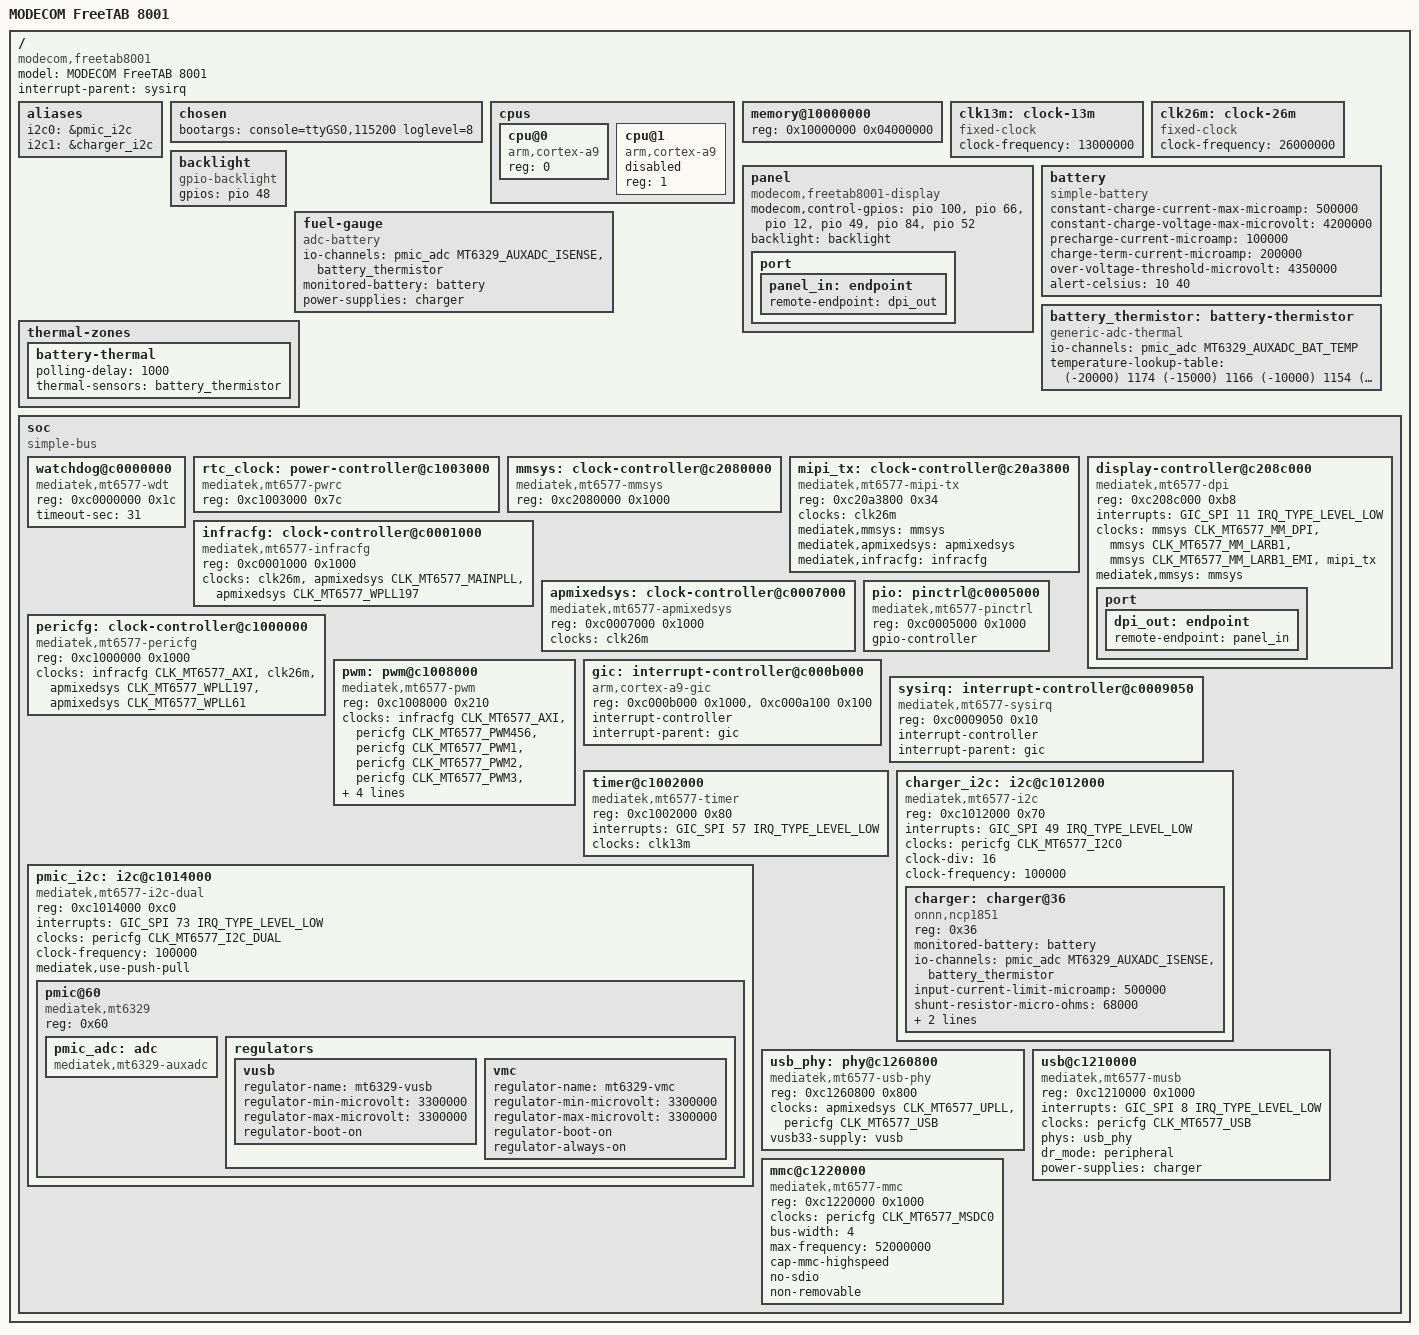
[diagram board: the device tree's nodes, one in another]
// SPDX-License-Identifier: GPL-2.0-only
/dts-v1/;

#include <dt-bindings/interrupt-controller/arm-gic.h>
#include <dt-bindings/interrupt-controller/irq.h>
#include <dt-bindings/clock/mediatek,mt6577-clk.h>
#include <dt-bindings/clock/mediatek,mt6577-mmsys.h>
#include <dt-bindings/gpio/gpio.h>
#include <dt-bindings/iio/adc/mediatek,mt6329-auxadc.h>

/ {
	model = "MODECOM FreeTAB 8001";
	compatible = "modecom,freetab8001", "mediatek,mt6577";
	#address-cells = <1>;
	#size-cells = <1>;
	interrupt-parent = <&sysirq>;

	aliases {
		i2c0 = &pmic_i2c;
		i2c1 = &charger_i2c;
	};

	chosen {
		bootargs = "console=ttyGS0,115200 loglevel=8";
	};

	cpus {
		#address-cells = <1>;
		#size-cells = <0>;

		cpu@0 {
			device_type = "cpu";
			compatible = "arm,cortex-a9";
			reg = <0>;
		};

		cpu@1 {
			device_type = "cpu";
			compatible = "arm,cortex-a9";
			reg = <1>;
			status = "disabled";
		};
	};

	memory@10000000 {
		device_type = "memory";
		reg = <0x10000000 0x04000000>;
	};

	clk13m: clock-13m {
		compatible = "fixed-clock";
		#clock-cells = <0>;
		clock-frequency = <13000000>;
	};

	clk26m: clock-26m {
		compatible = "fixed-clock";
		#clock-cells = <0>;
		clock-frequency = <26000000>;
	};

	backlight: backlight {
		compatible = "gpio-backlight";
		gpios = <&pio 48 GPIO_ACTIVE_HIGH>;
	};

	panel {
		compatible = "modecom,freetab8001-display";
		modecom,control-gpios = <&pio 100 GPIO_ACTIVE_HIGH>,
					<&pio 66 GPIO_ACTIVE_HIGH>,
					<&pio 12 GPIO_ACTIVE_HIGH>,
					<&pio 49 GPIO_ACTIVE_HIGH>,
					<&pio 84 GPIO_ACTIVE_HIGH>,
					<&pio 52 GPIO_ACTIVE_HIGH>;
		backlight = <&backlight>;

		port {
			panel_in: endpoint {
				remote-endpoint = <&dpi_out>;
			};
		};
	};

	battery: battery {
		compatible = "simple-battery";
		constant-charge-current-max-microamp = <500000>;
		constant-charge-voltage-max-microvolt = <4200000>;
		precharge-current-microamp = <100000>;
		charge-term-current-microamp = <200000>;
		over-voltage-threshold-microvolt = <4350000>;
		alert-celsius = <10 40>;
	};

	fuel-gauge {
		compatible = "adc-battery";
		io-channels = <&pmic_adc MT6329_AUXADC_ISENSE>,
			      <&battery_thermistor>;
		io-channel-names = "voltage", "temperature";
		monitored-battery = <&battery>;
		power-supplies = <&charger>;
	};

	battery_thermistor: battery-thermistor {
		compatible = "generic-adc-thermal";
		#thermal-sensor-cells = <0>;
		#io-channel-cells = <0>;
		io-channels = <&pmic_adc MT6329_AUXADC_BAT_TEMP>;
		io-channel-names = "sensor-channel";
		temperature-lookup-table = <
			(-20000) 1174
			(-15000) 1166
			(-10000) 1154
			(-5000) 1140
			0 1122
			5000 1101
			10000 1075
			15000 1044
			20000 1008
			25000 968
			30000 923
			35000 873
			40000 820
			45000 765
			50000 708
			55000 650
			60000 594
			65000 539
			70000 486>;
	};

	thermal-zones {
		battery-thermal {
			polling-delay = <1000>;
			thermal-sensors = <&battery_thermistor>;
		};
	};

	soc {
		compatible = "simple-bus";
		#address-cells = <1>;
		#size-cells = <1>;
		ranges;

		watchdog@c0000000 {
			compatible = "mediatek,mt6577-wdt";
			reg = <0xc0000000 0x1c>;
			timeout-sec = <31>;
		};

		rtc_clock: power-controller@c1003000 {
			compatible = "mediatek,mt6577-pwrc";
			reg = <0xc1003000 0x7c>;
			#clock-cells = <0>;
		};

		mmsys: clock-controller@c2080000 {
			compatible = "mediatek,mt6577-mmsys", "syscon";
			reg = <0xc2080000 0x1000>;
			#clock-cells = <1>;
		};

		mipi_tx: clock-controller@c20a3800 {
			compatible = "mediatek,mt6577-mipi-tx";
			reg = <0xc20a3800 0x34>;
			clocks = <&clk26m>;
			#clock-cells = <0>;
			mediatek,mmsys = <&mmsys>;
			mediatek,apmixedsys = <&apmixedsys>;
			mediatek,infracfg = <&infracfg>;
		};

		display-controller@c208c000 {
			compatible = "mediatek,mt6577-dpi";
			reg = <0xc208c000 0xb8>;
			interrupts = <GIC_SPI 11 IRQ_TYPE_LEVEL_LOW>;
			clocks = <&mmsys CLK_MT6577_MM_DPI>,
				 <&mmsys CLK_MT6577_MM_LARB1>,
				 <&mmsys CLK_MT6577_MM_LARB1_EMI>, <&mipi_tx>;
			clock-names = "engine", "larb", "larb-emi", "pll";
			mediatek,mmsys = <&mmsys>;

			port {
				dpi_out: endpoint {
					remote-endpoint = <&panel_in>;
				};
			};
		};

		infracfg: clock-controller@c0001000 {
			compatible = "mediatek,mt6577-infracfg";
			reg = <0xc0001000 0x1000>;
			clocks = <&clk26m>, <&apmixedsys CLK_MT6577_MAINPLL>,
				 <&apmixedsys CLK_MT6577_WPLL197>;
			clock-names = "clk26m", "mainpll", "wpll";
			#clock-cells = <1>;
		};

		apmixedsys: clock-controller@c0007000 {
			compatible = "mediatek,mt6577-apmixedsys";
			reg = <0xc0007000 0x1000>;
			clocks = <&clk26m>;
			clock-names = "clk26m";
			#clock-cells = <1>;
		};

		pericfg: clock-controller@c1000000 {
			compatible = "mediatek,mt6577-pericfg";
			reg = <0xc1000000 0x1000>;
			clocks = <&infracfg CLK_MT6577_AXI>, <&clk26m>,
				 <&apmixedsys CLK_MT6577_WPLL197>,
				 <&apmixedsys CLK_MT6577_WPLL61>;
			clock-names = "axi", "clk26m", "wpll197", "wpll61";
			#clock-cells = <1>;
		};

		pwm: pwm@c1008000 {
			compatible = "mediatek,mt6577-pwm";
			reg = <0xc1008000 0x210>;
			#pwm-cells = <2>;
			clocks = <&infracfg CLK_MT6577_AXI>, <&pericfg CLK_MT6577_PWM456>,
				 <&pericfg CLK_MT6577_PWM1>, <&pericfg CLK_MT6577_PWM2>,
				 <&pericfg CLK_MT6577_PWM3>, <&pericfg CLK_MT6577_PWM456>,
				 <&pericfg CLK_MT6577_PWM456>, <&pericfg CLK_MT6577_PWM456>,
				 <&pericfg CLK_MT6577_PWM7>;
			clock-names = "top", "main", "pwm1", "pwm2", "pwm3",
				      "pwm4", "pwm5", "pwm6", "pwm7";
		};

		pio: pinctrl@c0005000 {
			compatible = "mediatek,mt6577-pinctrl";
			reg = <0xc0005000 0x1000>;
			gpio-controller;
			#gpio-cells = <2>;
		};

		gic: interrupt-controller@c000b000 {
			compatible = "arm,cortex-a9-gic";
			reg = <0xc000b000 0x1000>, <0xc000a100 0x100>;
			interrupt-controller;
			#interrupt-cells = <3>;
			#address-cells = <0>;
			interrupt-parent = <&gic>;
		};

		sysirq: interrupt-controller@c0009050 {
			compatible = "mediatek,mt6577-sysirq";
			reg = <0xc0009050 0x10>;
			interrupt-controller;
			#interrupt-cells = <3>;
			#address-cells = <0>;
			interrupt-parent = <&gic>;
		};

		timer@c1002000 {
			compatible = "mediatek,mt6577-timer";
			reg = <0xc1002000 0x80>;
			interrupts = <GIC_SPI 57 IRQ_TYPE_LEVEL_LOW>;
			clocks = <&clk13m>;
			clock-names = "system-clk";
		};

		charger_i2c: i2c@c1012000 {
			compatible = "mediatek,mt6577-i2c";
			reg = <0xc1012000 0x70>;
			interrupts = <GIC_SPI 49 IRQ_TYPE_LEVEL_LOW>;
			clocks = <&pericfg CLK_MT6577_I2C0>;
			clock-names = "main";
			clock-div = <16>;
			clock-frequency = <100000>;
			#address-cells = <1>;
			#size-cells = <0>;

			charger: charger@36 {
				compatible = "onnn,ncp1851";
				reg = <0x36>;
				monitored-battery = <&battery>;
				io-channels = <&pmic_adc MT6329_AUXADC_ISENSE>,
					      <&battery_thermistor>;
				io-channel-names = "voltage", "temperature";
				input-current-limit-microamp = <500000>;
				shunt-resistor-micro-ohms = <68000>;
				onnn,power-path;
				onnn,system-voltage-microvolt = <3400000>;
			};
		};

		pmic_i2c: i2c@c1014000 {
			compatible = "mediatek,mt6577-i2c-dual";
			reg = <0xc1014000 0xc0>;
			interrupts = <GIC_SPI 73 IRQ_TYPE_LEVEL_LOW>;
			clocks = <&pericfg CLK_MT6577_I2C_DUAL>;
			clock-names = "main";
			clock-frequency = <100000>;
			mediatek,use-push-pull;
			#address-cells = <1>;
			#size-cells = <0>;

			pmic@60 {
				compatible = "mediatek,mt6329";
				reg = <0x60>;

				pmic_adc: adc {
					compatible = "mediatek,mt6329-auxadc";
					#io-channel-cells = <1>;
				};

				regulators {
					vusb: vusb {
						regulator-name = "mt6329-vusb";
						regulator-min-microvolt = <3300000>;
						regulator-max-microvolt = <3300000>;
						regulator-boot-on;
					};

					vmc: vmc {
						regulator-name = "mt6329-vmc";
						regulator-min-microvolt = <3300000>;
						regulator-max-microvolt = <3300000>;
						regulator-boot-on;
						regulator-always-on;
					};
				};
			};
		};

		usb_phy: phy@c1260800 {
			compatible = "mediatek,mt6577-usb-phy";
			reg = <0xc1260800 0x800>;
			clocks = <&apmixedsys CLK_MT6577_UPLL>, <&pericfg CLK_MT6577_USB>;
			clock-names = "upll", "bus";
			vusb33-supply = <&vusb>;
			#phy-cells = <0>;
		};

		usb@c1210000 {
			compatible = "mediatek,mt6577-musb";
			reg = <0xc1210000 0x1000>;
			interrupts = <GIC_SPI 8 IRQ_TYPE_LEVEL_LOW>;
			interrupt-names = "mc";
			clocks = <&pericfg CLK_MT6577_USB>;
			clock-names = "bus";
			phys = <&usb_phy>;
			phy-names = "usb2-phy";
			dr_mode = "peripheral";
			power-supplies = <&charger>;
		};

		mmc@c1220000 {
			compatible = "mediatek,mt6577-mmc";
			reg = <0xc1220000 0x1000>;
			clocks = <&pericfg CLK_MT6577_MSDC0>;
			clock-names = "source";
			bus-width = <4>;
			max-frequency = <52000000>;
			cap-mmc-highspeed;
			no-sdio;
			non-removable;
		};
	};
};
